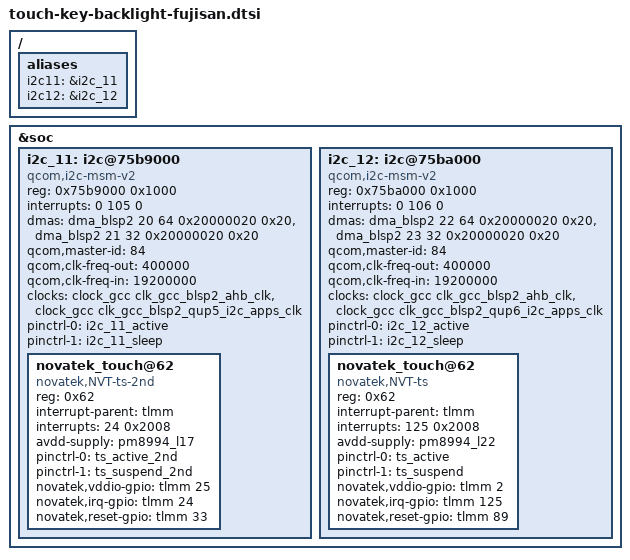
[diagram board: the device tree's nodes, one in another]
/ {
	aliases {
		i2c11 = &i2c_11;
		i2c12 = &i2c_12;
	};
};

&soc {
	i2c_11: i2c@75b9000 {
		compatible = "qcom,i2c-msm-v2";
		#address-cells = <1>;
		#size-cells = <0>;
		reg-names = "qup_phys_addr";
		reg = <0x75b9000 0x1000>;
		interrupt-names = "qup_irq";
		interrupts = <0 105 0>;
		dmas = <&dma_blsp2 20 64 0x20000020 0x20>,
			<&dma_blsp2 21 32 0x20000020 0x20>;
		dma-names = "tx", "rx";
		qcom,master-id = <84>;
		qcom,clk-freq-out = <400000>;
		qcom,clk-freq-in  = <19200000>;
		clock-names = "iface_clk", "core_clk";
		clocks = <&clock_gcc clk_gcc_blsp2_ahb_clk>,
			 <&clock_gcc clk_gcc_blsp2_qup5_i2c_apps_clk>;
		pinctrl-names = "i2c_active", "i2c_sleep";
		pinctrl-0 = <&i2c_11_active>;
		pinctrl-1 = <&i2c_11_sleep>;
		};

	i2c_12: i2c@75ba000 {
		compatible = "qcom,i2c-msm-v2";
		#address-cells = <1>;
		#size-cells = <0>;
		reg-names = "qup_phys_addr";
		reg = <0x75ba000 0x1000>;
		interrupt-names = "qup_irq";
		interrupts = <0 106 0>;
		dmas = <&dma_blsp2 22 64 0x20000020 0x20>,
			<&dma_blsp2 23 32 0x20000020 0x20>;
		dma-names = "tx", "rx";
		qcom,master-id = <84>;
		qcom,clk-freq-out = <400000>;
		qcom,clk-freq-in  = <19200000>;
		clock-names = "iface_clk", "core_clk";
		clocks = <&clock_gcc clk_gcc_blsp2_ahb_clk>,
			 <&clock_gcc clk_gcc_blsp2_qup6_i2c_apps_clk>;
		pinctrl-names = "i2c_active", "i2c_sleep";
		pinctrl-0 = <&i2c_12_active>;
		pinctrl-1 = <&i2c_12_sleep>;
		};
};


	&i2c_12 { /* BLSP1 QUP12 */
		novatek_touch@62 {
			compatible = "novatek,NVT-ts";
			reg = <0x62>;
			interrupt-parent = <&tlmm>;
			interrupts = <125 0x2008>;
			/* vdd-supply = <&pm8994_l22>; */
			avdd-supply = <&pm8994_l22>;
			pinctrl-names = "default", "sleep";
			pinctrl-0 = <&ts_active>;
			pinctrl-1 = <&ts_suspend>;
			novatek,vddio-gpio = <&tlmm 2 0x00>;
			novatek,irq-gpio = <&tlmm 125 0x2008>;
			novatek,reset-gpio = <&tlmm 89 0x00>;
		};
	};

	&i2c_11 { /* BLSP1 QUP12 */
		novatek_touch@62 {
			compatible = "novatek,NVT-ts-2nd";
			reg = <0x62>;
			interrupt-parent = <&tlmm>;
			interrupts = <24 0x2008>;
			/* vdd-supply = <&pm8994_l17>; */
			avdd-supply = <&pm8994_l17>;
			pinctrl-names = "default", "sleep";
			pinctrl-0 = <&ts_active_2nd>;
			pinctrl-1 = <&ts_suspend_2nd>;
			novatek,vddio-gpio = <&tlmm 25 0x00>;
			novatek,irq-gpio = <&tlmm 24 0x2008>;
			novatek,reset-gpio = <&tlmm 33 0x00>;
		};
	};
